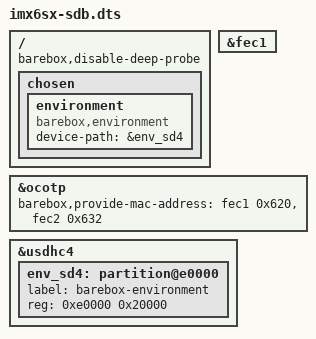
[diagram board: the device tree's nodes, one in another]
/*
 * The code contained herein is licensed under the GNU General Public
 * License. You may obtain a copy of the GNU General Public License
 * Version 2 or later at the following locations:
 *
 * http://www.opensource.org/licenses/gpl-license.html
 * http://www.gnu.org/copyleft/gpl.html
 */

#include <arm/nxp/imx/imx6sx-sdb.dts>
#include "imx6sx.dtsi"

/ {
	barebox,disable-deep-probe;

	chosen {
		environment {
			compatible = "barebox,environment";
			device-path = &env_sd4;
		};
	};
};

&fec1 {
	/delete-property/ phy-reset-gpios;
};

&ocotp {
	barebox,provide-mac-address = <&fec1 0x620 &fec2 0x632>;
};

&usdhc4 {
	#address-cells = <1>;
	#size-cells = <1>;

	env_sd4: partition@e0000 {
		label = "barebox-environment";
		reg = <0xe0000 0x20000>;
	};
};
